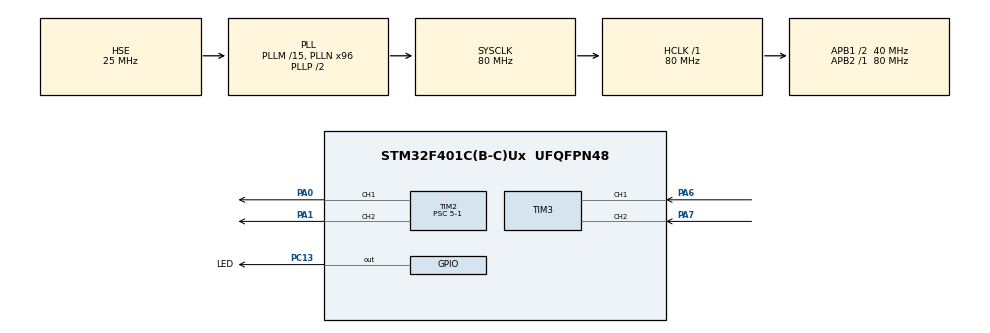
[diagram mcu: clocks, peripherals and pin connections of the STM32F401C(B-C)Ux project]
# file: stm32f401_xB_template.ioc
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Mcu.Family=STM32F4
Mcu.Name=STM32F401C(B-C)Ux
Mcu.Package=UFQFPN48
NVIC.PriorityGroup=NVIC_PRIORITYGROUP_4
PA0-WKUP.Signal=S_TIM2_CH1_ETR
PA1.Signal=S_TIM2_CH2
PA13.Mode=Trace_Asynchronous_SW
PA13.Signal=SYS_JTMS-SWDIO
PA14.Mode=Trace_Asynchronous_SW
PA14.Signal=SYS_JTCK-SWCLK
PA6.Signal=S_TIM3_CH1
PA7.Signal=S_TIM3_CH2
PB3.Mode=Trace_Asynchronous_SW
PB3.Signal=SYS_JTDO-SWO
PC13-ANTI_TAMP.GPIO_Label=LED
PC13-ANTI_TAMP.Signal=GPIO_Output
PH0\ -\ OSC_IN.Mode=HSE-External-Oscillator
PH0\ -\ OSC_IN.Signal=RCC_OSC_IN
PH1\ -\ OSC_OUT.Mode=HSE-External-Oscillator
PH1\ -\ OSC_OUT.Signal=RCC_OSC_OUT
ProjectManager.HeapSize=0x200
ProjectManager.StackSize=0x400
ProjectManager.TargetToolchain=STM32CubeIDE
RCC.48MHZClocksFreq_Value=40000000
RCC.AHBFreq_Value=80000000
RCC.APB1CLKDivider=RCC_HCLK_DIV2
RCC.APB1Freq_Value=40000000
RCC.APB1TimFreq_Value=80000000
RCC.APB2Freq_Value=80000000
RCC.APB2TimFreq_Value=80000000
RCC.CortexFreq_Value=80000000
RCC.HCLKFreq_Value=80000000
RCC.HSE_VALUE=25000000
RCC.HSI_VALUE=16000000
RCC.LSE_VALUE=32768
RCC.PLLM=15
RCC.PLLN=96
RCC.PLLSourceVirtual=RCC_PLLSOURCE_HSE
RCC.SYSCLKFreq_VALUE=80000000
RCC.SYSCLKSource=RCC_SYSCLKSOURCE_PLLCLK
RCC.VCOOutputFreq_Value=160000000
SH.S_TIM2_CH1_ETR.0=TIM2_CH1,PWM Generation1 CH1
SH.S_TIM2_CH2.0=TIM2_CH2,PWM Generation2 CH2
SH.S_TIM3_CH1.0=TIM3_CH1,Encoder_Interface
SH.S_TIM3_CH2.0=TIM3_CH2,Encoder_Interface
TIM2.Channel-PWM\ Generation1\ CH1=TIM_CHANNEL_1
TIM2.Channel-PWM\ Generation2\ CH2=TIM_CHANNEL_2
TIM2.Period=1000
TIM2.Prescaler=5-1
TIM3.EncoderMode=TIM_ENCODERMODE_TI12
VP_TIM2_VS_ClockSourceINT.Mode=Internal
board=custom

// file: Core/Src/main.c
/* USER CODE BEGIN Header */
/**
  ******************************************************************************
  * @file           : main.c
  * @brief          : Main program body
  ******************************************************************************
  * @attention
  *
  * Copyright (c) 2022 STMicroelectronics.
  * All rights reserved.
  *
  * This software is licensed under terms that can be found in the LICENSE file
  * in the root directory of this software component.
  * If no LICENSE file comes with this software, it is provided AS-IS.
  *
  ******************************************************************************
  */
/* USER CODE END Header */
#include "main.h"

/* USER CODE BEGIN Includes */
#include <dataAcq.h>
/* USER CODE END Includes */

TIM_HandleTypeDef htim2;
TIM_HandleTypeDef htim3;

void SystemClock_Config(void);
static void MX_GPIO_Init(void);
static void MX_TIM2_Init(void);
static void MX_TIM3_Init(void);

int main(void)
{

  /* MCU Configuration--------------------------------------------------------*/

  /* Reset of all peripherals, Initializes the Flash interface and the Systick. */
  HAL_Init();

  /* Configure the system clock */
  SystemClock_Config();

  /* USER CODE BEGIN SysInit */
  HAL_SYSTICK_Config(HAL_RCC_GetHCLKFreq()/200);//80000000/200=>400000ticks,400000ticks at 80MHz = 5ms
  /* USER CODE END SysInit */

  /* Initialize all configured peripherals */
  MX_GPIO_Init();
  MX_TIM2_Init();
  MX_TIM3_Init();
  /* USER CODE BEGIN 2 */
  HAL_TIM_PWM_Start(&htim2, TIM_CHANNEL_1);
  HAL_TIM_PWM_Start(&htim2, TIM_CHANNEL_2);
  HAL_TIM_Encoder_Start(&htim3, TIM_CHANNEL_ALL);

  /* USER CODE END 2 */

  /* Infinite loop */
  while (1)
  {

  }
}

void SystemClock_Config(void)
{
  RCC_OscInitTypeDef RCC_OscInitStruct = {0};
  RCC_ClkInitTypeDef RCC_ClkInitStruct = {0};

  /** Configure the main internal regulator output voltage
  */
  __HAL_RCC_PWR_CLK_ENABLE();
  __HAL_PWR_VOLTAGESCALING_CONFIG(PWR_REGULATOR_VOLTAGE_SCALE2);

  /** Initializes the RCC Oscillators according to the specified parameters
  * in the RCC_OscInitTypeDef structure.
  */
  RCC_OscInitStruct.OscillatorType = RCC_OSCILLATORTYPE_HSE;
  RCC_OscInitStruct.HSEState = RCC_HSE_ON;
  RCC_OscInitStruct.PLL.PLLState = RCC_PLL_ON;
  RCC_OscInitStruct.PLL.PLLSource = RCC_PLLSOURCE_HSE;
  RCC_OscInitStruct.PLL.PLLM = 15;
  RCC_OscInitStruct.PLL.PLLN = 96;
  RCC_OscInitStruct.PLL.PLLP = RCC_PLLP_DIV2;
  RCC_OscInitStruct.PLL.PLLQ = 4;
  if (HAL_RCC_OscConfig(&RCC_OscInitStruct) != HAL_OK)
  {
    Error_Handler();
  }

  /** Initializes the CPU, AHB and APB buses clocks
  */
  RCC_ClkInitStruct.ClockType = RCC_CLOCKTYPE_HCLK|RCC_CLOCKTYPE_SYSCLK
                              |RCC_CLOCKTYPE_PCLK1|RCC_CLOCKTYPE_PCLK2;
  RCC_ClkInitStruct.SYSCLKSource = RCC_SYSCLKSOURCE_PLLCLK;
  RCC_ClkInitStruct.AHBCLKDivider = RCC_SYSCLK_DIV1;
  RCC_ClkInitStruct.APB1CLKDivider = RCC_HCLK_DIV2;
  RCC_ClkInitStruct.APB2CLKDivider = RCC_HCLK_DIV1;

  if (HAL_RCC_ClockConfig(&RCC_ClkInitStruct, FLASH_LATENCY_2) != HAL_OK)
  {
    Error_Handler();
  }
}

static void MX_TIM2_Init(void)
{

  TIM_ClockConfigTypeDef sClockSourceConfig = {0};
  TIM_MasterConfigTypeDef sMasterConfig = {0};
  TIM_OC_InitTypeDef sConfigOC = {0};

  htim2.Instance = TIM2;
  htim2.Init.Prescaler = 5-1;
  htim2.Init.CounterMode = TIM_COUNTERMODE_UP;
  htim2.Init.Period = 1000;
  htim2.Init.ClockDivision = TIM_CLOCKDIVISION_DIV1;
  htim2.Init.AutoReloadPreload = TIM_AUTORELOAD_PRELOAD_DISABLE;
  if (HAL_TIM_Base_Init(&htim2) != HAL_OK)
  {
    Error_Handler();
  }
  sClockSourceConfig.ClockSource = TIM_CLOCKSOURCE_INTERNAL;
  if (HAL_TIM_ConfigClockSource(&htim2, &sClockSourceConfig) != HAL_OK)
  {
    Error_Handler();
  }
  if (HAL_TIM_PWM_Init(&htim2) != HAL_OK)
  {
    Error_Handler();
  }
  sMasterConfig.MasterOutputTrigger = TIM_TRGO_RESET;
  sMasterConfig.MasterSlaveMode = TIM_MASTERSLAVEMODE_DISABLE;
  if (HAL_TIMEx_MasterConfigSynchronization(&htim2, &sMasterConfig) != HAL_OK)
  {
    Error_Handler();
  }
  sConfigOC.OCMode = TIM_OCMODE_PWM1;
  sConfigOC.Pulse = 0;
  sConfigOC.OCPolarity = TIM_OCPOLARITY_HIGH;
  sConfigOC.OCFastMode = TIM_OCFAST_DISABLE;
  if (HAL_TIM_PWM_ConfigChannel(&htim2, &sConfigOC, TIM_CHANNEL_1) != HAL_OK)
  {
    Error_Handler();
  }
  if (HAL_TIM_PWM_ConfigChannel(&htim2, &sConfigOC, TIM_CHANNEL_2) != HAL_OK)
  {
    Error_Handler();
  }
  HAL_TIM_MspPostInit(&htim2);

}

static void MX_TIM3_Init(void)
{

  TIM_Encoder_InitTypeDef sConfig = {0};
  TIM_MasterConfigTypeDef sMasterConfig = {0};

  htim3.Instance = TIM3;
  htim3.Init.Prescaler = 0;
  htim3.Init.CounterMode = TIM_COUNTERMODE_UP;
  htim3.Init.Period = 65535;
  htim3.Init.ClockDivision = TIM_CLOCKDIVISION_DIV1;
  htim3.Init.AutoReloadPreload = TIM_AUTORELOAD_PRELOAD_DISABLE;
  sConfig.EncoderMode = TIM_ENCODERMODE_TI12;
  sConfig.IC1Polarity = TIM_ICPOLARITY_RISING;
  sConfig.IC1Selection = TIM_ICSELECTION_DIRECTTI;
  sConfig.IC1Prescaler = TIM_ICPSC_DIV1;
  sConfig.IC1Filter = 0;
  sConfig.IC2Polarity = TIM_ICPOLARITY_RISING;
  sConfig.IC2Selection = TIM_ICSELECTION_DIRECTTI;
  sConfig.IC2Prescaler = TIM_ICPSC_DIV1;
  sConfig.IC2Filter = 0;
  if (HAL_TIM_Encoder_Init(&htim3, &sConfig) != HAL_OK)
  {
    Error_Handler();
  }
  sMasterConfig.MasterOutputTrigger = TIM_TRGO_RESET;
  sMasterConfig.MasterSlaveMode = TIM_MASTERSLAVEMODE_DISABLE;
  if (HAL_TIMEx_MasterConfigSynchronization(&htim3, &sMasterConfig) != HAL_OK)
  {
    Error_Handler();
  }

}

static void MX_GPIO_Init(void)
{
  GPIO_InitTypeDef GPIO_InitStruct = {0};

  /* GPIO Ports Clock Enable */
  __HAL_RCC_GPIOC_CLK_ENABLE();
  __HAL_RCC_GPIOH_CLK_ENABLE();
  __HAL_RCC_GPIOA_CLK_ENABLE();
  __HAL_RCC_GPIOB_CLK_ENABLE();

  /*Configure GPIO pin Output Level */
  HAL_GPIO_WritePin(LED_GPIO_Port, LED_Pin, GPIO_PIN_RESET);

  /*Configure GPIO pin : LED_Pin */
  GPIO_InitStruct.Pin = LED_Pin;
  GPIO_InitStruct.Mode = GPIO_MODE_OUTPUT_PP;
  GPIO_InitStruct.Pull = GPIO_NOPULL;
  GPIO_InitStruct.Speed = GPIO_SPEED_FREQ_LOW;
  HAL_GPIO_Init(LED_GPIO_Port, &GPIO_InitStruct);

}

void Error_Handler(void)
{
  __disable_irq();
  while (1)
  {
  }
}
